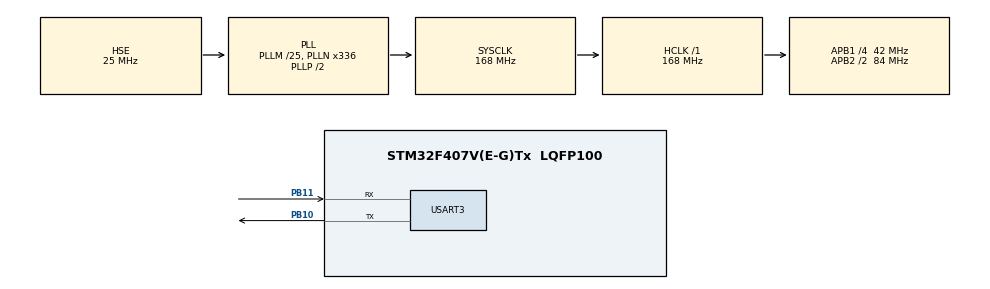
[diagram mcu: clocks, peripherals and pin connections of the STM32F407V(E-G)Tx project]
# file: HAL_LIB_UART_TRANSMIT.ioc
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Mcu.Family=STM32F4
Mcu.Name=STM32F407V(E-G)Tx
Mcu.Package=LQFP100
NVIC.PriorityGroup=NVIC_PRIORITYGROUP_4
PB10.Mode=Asynchronous
PB10.Signal=USART3_TX
PB11.Mode=Asynchronous
PB11.Signal=USART3_RX
PH0-OSC_IN.Mode=HSE-External-Oscillator
PH0-OSC_IN.Signal=RCC_OSC_IN
PH1-OSC_OUT.Mode=HSE-External-Oscillator
PH1-OSC_OUT.Signal=RCC_OSC_OUT
ProjectManager.HeapSize=0x200
ProjectManager.StackSize=0x400
ProjectManager.TargetToolchain=STM32CubeIDE
RCC.48MHZClocksFreq_Value=84000000
RCC.AHBFreq_Value=168000000
RCC.APB1CLKDivider=RCC_HCLK_DIV4
RCC.APB1Freq_Value=42000000
RCC.APB1TimFreq_Value=84000000
RCC.APB2CLKDivider=RCC_HCLK_DIV2
RCC.APB2Freq_Value=84000000
RCC.APB2TimFreq_Value=168000000
RCC.CortexFreq_Value=168000000
RCC.HCLKFreq_Value=168000000
RCC.HSE_VALUE=25000000
RCC.HSI_VALUE=16000000
RCC.LSE_VALUE=32768
RCC.PLLM=25
RCC.PLLN=336
RCC.PLLSourceVirtual=RCC_PLLSOURCE_HSE
RCC.SYSCLKFreq_VALUE=168000000
RCC.SYSCLKSource=RCC_SYSCLKSOURCE_PLLCLK
RCC.VCOOutputFreq_Value=336000000
USART3.VirtualMode=VM_ASYNC
board=custom

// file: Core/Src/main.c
/* USER CODE BEGIN Header */
/**
  ******************************************************************************
  * @file           : main.c
  * @brief          : Main program body
  ******************************************************************************
  * @attention
  *
  * Copyright (c) 2021 STMicroelectronics.
  * All rights reserved.
  *
  * This software is licensed under terms that can be found in the LICENSE file
  * in the root directory of this software component.
  * If no LICENSE file comes with this software, it is provided AS-IS.
  *
  ******************************************************************************
  */
/* USER CODE END Header */
#include "main.h"

/* USER CODE BEGIN Includes */
#include "stdio.h"
#include "string.h"
/* USER CODE END Includes */

UART_HandleTypeDef huart3;

/* USER CODE BEGIN PV */

char tx[50];
uint8_t data[] = "HELLO WORLD \r\n";

/* USER CODE END PV */

void SystemClock_Config(void);
static void MX_GPIO_Init(void);
static void MX_USART3_UART_Init(void);

int main(void)
{

  /* MCU Configuration--------------------------------------------------------*/

  /* Reset of all peripherals, Initializes the Flash interface and the Systick. */
  HAL_Init();

  /* Configure the system clock */
  SystemClock_Config();

  /* Initialize all configured peripherals */
  MX_GPIO_Init();
  MX_USART3_UART_Init();
  /* USER CODE BEGIN 2 */

  //HAL_UART_Transmit(&huart2, (uint8_t *)tx, sprintf(tx,"deneme\n"), 100);
  //HAL_UART_Transmit (&huart3, data, sizeof (data), 10);

  /* USER CODE END 2 */

  /* Infinite loop */
  while (1)
  {

    /* USER CODE BEGIN 3 */
	  HAL_UART_Transmit (&huart3, data, sprintf(tx,"Hello World") , 1000);
  }
  /* USER CODE END 3 */
}

void SystemClock_Config(void)
{
  RCC_OscInitTypeDef RCC_OscInitStruct = {0};
  RCC_ClkInitTypeDef RCC_ClkInitStruct = {0};

  /** Configure the main internal regulator output voltage
  */
  __HAL_RCC_PWR_CLK_ENABLE();
  __HAL_PWR_VOLTAGESCALING_CONFIG(PWR_REGULATOR_VOLTAGE_SCALE1);
  /** Initializes the RCC Oscillators according to the specified parameters
  * in the RCC_OscInitTypeDef structure.
  */
  RCC_OscInitStruct.OscillatorType = RCC_OSCILLATORTYPE_HSE;
  RCC_OscInitStruct.HSEState = RCC_HSE_ON;
  RCC_OscInitStruct.PLL.PLLState = RCC_PLL_ON;
  RCC_OscInitStruct.PLL.PLLSource = RCC_PLLSOURCE_HSE;
  RCC_OscInitStruct.PLL.PLLM = 25;
  RCC_OscInitStruct.PLL.PLLN = 336;
  RCC_OscInitStruct.PLL.PLLP = RCC_PLLP_DIV2;
  RCC_OscInitStruct.PLL.PLLQ = 4;
  if (HAL_RCC_OscConfig(&RCC_OscInitStruct) != HAL_OK)
  {
    Error_Handler();
  }
  /** Initializes the CPU, AHB and APB buses clocks
  */
  RCC_ClkInitStruct.ClockType = RCC_CLOCKTYPE_HCLK|RCC_CLOCKTYPE_SYSCLK
                              |RCC_CLOCKTYPE_PCLK1|RCC_CLOCKTYPE_PCLK2;
  RCC_ClkInitStruct.SYSCLKSource = RCC_SYSCLKSOURCE_PLLCLK;
  RCC_ClkInitStruct.AHBCLKDivider = RCC_SYSCLK_DIV1;
  RCC_ClkInitStruct.APB1CLKDivider = RCC_HCLK_DIV4;
  RCC_ClkInitStruct.APB2CLKDivider = RCC_HCLK_DIV2;

  if (HAL_RCC_ClockConfig(&RCC_ClkInitStruct, FLASH_LATENCY_5) != HAL_OK)
  {
    Error_Handler();
  }
}

static void MX_USART3_UART_Init(void)
{

  huart3.Instance = USART3;
  huart3.Init.BaudRate = 115200;
  huart3.Init.WordLength = UART_WORDLENGTH_8B;
  huart3.Init.StopBits = UART_STOPBITS_1;
  huart3.Init.Parity = UART_PARITY_NONE;
  huart3.Init.Mode = UART_MODE_TX_RX;
  huart3.Init.HwFlowCtl = UART_HWCONTROL_NONE;
  huart3.Init.OverSampling = UART_OVERSAMPLING_16;
  if (HAL_UART_Init(&huart3) != HAL_OK)
  {
    Error_Handler();
  }

}

static void MX_GPIO_Init(void)
{

  /* GPIO Ports Clock Enable */
  __HAL_RCC_GPIOH_CLK_ENABLE();
  __HAL_RCC_GPIOB_CLK_ENABLE();

}

void Error_Handler(void)
{
  __disable_irq();
  while (1)
  {
  }
}
